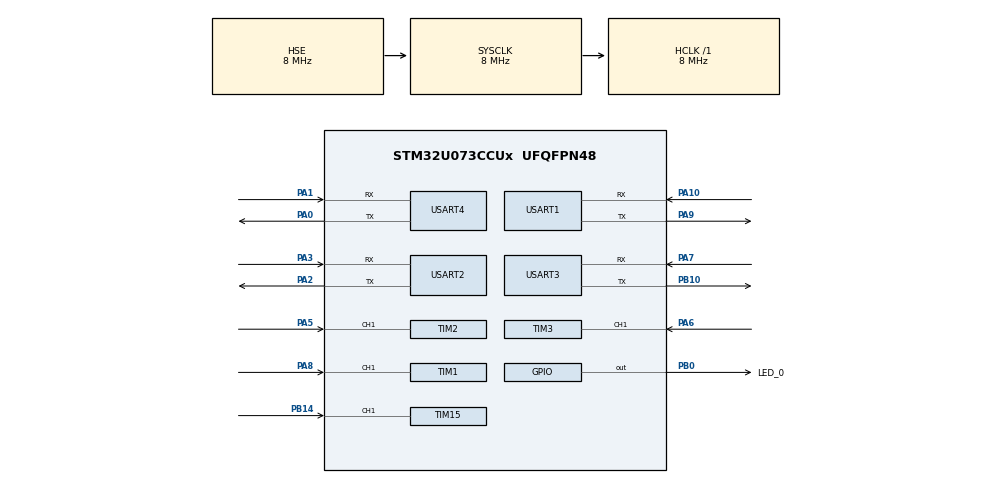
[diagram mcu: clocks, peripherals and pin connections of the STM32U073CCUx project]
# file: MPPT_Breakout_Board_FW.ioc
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Dma.Request0=USART4_RX
Dma.Request1=USART4_TX
Dma.Request2=USART3_RX
Dma.Request3=USART3_TX
Dma.USART3_RX.2.Direction=DMA_PERIPH_TO_MEMORY
Dma.USART3_RX.2.EventEnable=DISABLE
Dma.USART3_RX.2.Instance=DMA1_Channel3
Dma.USART3_RX.2.MemDataAlignment=DMA_MDATAALIGN_BYTE
Dma.USART3_RX.2.MemInc=DMA_MINC_ENABLE
Dma.USART3_RX.2.Mode=DMA_NORMAL
Dma.USART3_RX.2.PeriphDataAlignment=DMA_PDATAALIGN_BYTE
Dma.USART3_RX.2.PeriphInc=DMA_PINC_DISABLE
Dma.USART3_RX.2.Polarity=HAL_DMAMUX_REQ_GEN_RISING
Dma.USART3_RX.2.Priority=DMA_PRIORITY_LOW
Dma.USART3_RX.2.RequestNumber=1
Dma.USART3_RX.2.SignalID=NONE
Dma.USART3_RX.2.SyncEnable=DISABLE
Dma.USART3_RX.2.SyncPolarity=HAL_DMAMUX_SYNC_NO_EVENT
Dma.USART3_RX.2.SyncRequestNumber=1
Dma.USART3_RX.2.SyncSignalID=NONE
Dma.USART3_TX.3.Direction=DMA_MEMORY_TO_PERIPH
Dma.USART3_TX.3.EventEnable=DISABLE
Dma.USART3_TX.3.Instance=DMA1_Channel4
Dma.USART3_TX.3.MemDataAlignment=DMA_MDATAALIGN_BYTE
Dma.USART3_TX.3.MemInc=DMA_MINC_ENABLE
Dma.USART3_TX.3.Mode=DMA_NORMAL
Dma.USART3_TX.3.PeriphDataAlignment=DMA_PDATAALIGN_BYTE
Dma.USART3_TX.3.PeriphInc=DMA_PINC_DISABLE
Dma.USART3_TX.3.Polarity=HAL_DMAMUX_REQ_GEN_RISING
Dma.USART3_TX.3.Priority=DMA_PRIORITY_LOW
Dma.USART3_TX.3.RequestNumber=1
Dma.USART3_TX.3.SignalID=NONE
Dma.USART3_TX.3.SyncEnable=DISABLE
Dma.USART3_TX.3.SyncPolarity=HAL_DMAMUX_SYNC_NO_EVENT
Dma.USART3_TX.3.SyncRequestNumber=1
Dma.USART3_TX.3.SyncSignalID=NONE
Dma.USART4_RX.0.Direction=DMA_PERIPH_TO_MEMORY
Dma.USART4_RX.0.EventEnable=DISABLE
Dma.USART4_RX.0.Instance=DMA1_Channel1
Dma.USART4_RX.0.MemDataAlignment=DMA_MDATAALIGN_BYTE
Dma.USART4_RX.0.MemInc=DMA_MINC_ENABLE
Dma.USART4_RX.0.Mode=DMA_NORMAL
Dma.USART4_RX.0.PeriphDataAlignment=DMA_PDATAALIGN_BYTE
Dma.USART4_RX.0.PeriphInc=DMA_PINC_DISABLE
Dma.USART4_RX.0.Polarity=HAL_DMAMUX_REQ_GEN_RISING
Dma.USART4_RX.0.Priority=DMA_PRIORITY_LOW
Dma.USART4_RX.0.RequestNumber=1
Dma.USART4_RX.0.SignalID=NONE
Dma.USART4_RX.0.SyncEnable=DISABLE
Dma.USART4_RX.0.SyncPolarity=HAL_DMAMUX_SYNC_NO_EVENT
Dma.USART4_RX.0.SyncRequestNumber=1
Dma.USART4_RX.0.SyncSignalID=NONE
Dma.USART4_TX.1.Direction=DMA_MEMORY_TO_PERIPH
Dma.USART4_TX.1.EventEnable=DISABLE
Dma.USART4_TX.1.Instance=DMA1_Channel2
Dma.USART4_TX.1.MemDataAlignment=DMA_MDATAALIGN_BYTE
Dma.USART4_TX.1.MemInc=DMA_MINC_ENABLE
Dma.USART4_TX.1.Mode=DMA_NORMAL
Dma.USART4_TX.1.PeriphDataAlignment=DMA_PDATAALIGN_BYTE
Dma.USART4_TX.1.PeriphInc=DMA_PINC_DISABLE
Dma.USART4_TX.1.Polarity=HAL_DMAMUX_REQ_GEN_RISING
Dma.USART4_TX.1.Priority=DMA_PRIORITY_LOW
Dma.USART4_TX.1.RequestNumber=1
Dma.USART4_TX.1.SignalID=NONE
Dma.USART4_TX.1.SyncEnable=DISABLE
Dma.USART4_TX.1.SyncPolarity=HAL_DMAMUX_SYNC_NO_EVENT
Dma.USART4_TX.1.SyncRequestNumber=1
Dma.USART4_TX.1.SyncSignalID=NONE
Mcu.Family=STM32U0
Mcu.Name=STM32U073CCUx
Mcu.Package=UFQFPN48
NVIC.DMA1_Ch4_7_DMA2_Ch1_5_DMAMUX_OVR_IRQn=true\:0\:0\:false\:false\:true\:false\:true\:true
NVIC.DMA1_Channel1_IRQn=true\:0\:0\:false\:false\:true\:false\:true\:true
NVIC.DMA1_Channel2_3_IRQn=true\:0\:0\:false\:false\:true\:false\:true\:true
NVIC.PriorityGroup=NVIC_PRIORITYGROUP_2
NVIC.USART3_LPUART1_IRQn=true\:0\:0\:false\:false\:true\:true\:true\:true
NVIC.USART4_LPUART3_IRQn=true\:0\:0\:false\:false\:true\:true\:true\:true
PA0.Mode=Asynchronous
PA0.Signal=USART4_TX
PA1.Mode=Asynchronous
PA1.Signal=USART4_RX
PA10.Mode=Asynchronous
PA10.Signal=USART1_RX
PA13\ (SWDIO).Mode=Serial_Wire
PA13\ (SWDIO).Signal=DEBUG_JTMS-SWDIO
PA14\ (SWCLK).Mode=Serial_Wire
PA14\ (SWCLK).Signal=DEBUG_JTCK-SWCLK
PA2.Mode=Asynchronous
PA2.Signal=USART2_TX
PA3.Mode=Asynchronous
PA3.Signal=USART2_RX
PA5.Signal=S_TIM2_CH1_ETR
PA6.Signal=S_TIM3_CH1
PA7.Mode=Asynchronous
PA7.Signal=USART3_RX
PA8.Signal=S_TIM1_CH1
PA9.Mode=Asynchronous
PA9.Signal=USART1_TX
PB0.GPIO_Label=LED_0
PB0.Signal=GPIO_Output
PB10.Mode=Asynchronous
PB10.Signal=USART3_TX
PB14.Signal=S_TIM15_CH1
PF0-OSC_IN.Mode=HSE-External-Oscillator
PF0-OSC_IN.Signal=RCC_OSC_IN
PF1-OSC_OUT.Mode=HSE-External-Oscillator
PF1-OSC_OUT.Signal=RCC_OSC_OUT
ProjectManager.HeapSize=0x200
ProjectManager.StackSize=0x400
ProjectManager.TargetToolchain=CMake
RCC.ADCFreq_Value=8000000
RCC.AHBFreq_Value=8000000
RCC.CortexFreq_Value=8000000
RCC.HCLKFreq_Value=8000000
RCC.HSE_VALUE=8000000
RCC.HSI48_VALUE=48000000
RCC.HSI_VALUE=16000000
RCC.LSE_VALUE=32768
RCC.MSI_VALUE=4000000
RCC.PLLSourceVirtual=RCC_PLLSOURCE_HSE
RCC.SYSCLKFreq_VALUE=8000000
RCC.SYSCLKSource=RCC_SYSCLKSOURCE_HSE
RCC.VCOOutputFreq_Value=32000000
SH.S_TIM15_CH1.0=TIM15_CH1,Input_Capture1_from_TI1
SH.S_TIM1_CH1.0=TIM1_CH1,Input_Capture1_from_TI1
SH.S_TIM2_CH1_ETR.0=TIM2_CH1,Input_Capture1_from_TI1
SH.S_TIM3_CH1.0=TIM3_CH1,Input_Capture1_from_TI1
TIM1.Channel-Input_Capture1_from_TI1=TIM_CHANNEL_1
TIM15.Channel-Input_Capture1_from_TI1=TIM_CHANNEL_1
TIM2.Channel-Input_Capture1_from_TI1=TIM_CHANNEL_1
TIM3.Channel-Input_Capture1_from_TI1=TIM_CHANNEL_1
USART1.VirtualMode-Asynchronous=VM_ASYNC
USART2.VirtualMode-Asynchronous=VM_ASYNC
USART3.VirtualMode-Asynchronous=VM_ASYNC
USART4.VirtualMode-Asynchronous=VM_ASYNC
VP_PWR_VS_SECSignals.Mode=Security/Privilege
VP_TIM1_VS_ClockSourceINT.Mode=Internal
VP_TIM2_VS_ClockSourceINT.Mode=Internal
board=custom

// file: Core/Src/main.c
/* USER CODE BEGIN Header */
/**
  ******************************************************************************
  * @file           : main.c
  * @brief          : Main program body
  ******************************************************************************
  * @attention
  *
  * Copyright (c) 2024 STMicroelectronics.
  * All rights reserved.
  *
  * This software is licensed under terms that can be found in the LICENSE file
  * in the root directory of this software component.
  * If no LICENSE file comes with this software, it is provided AS-IS.
  *
  ******************************************************************************
  */
/* USER CODE END Header */
#include "main.h"
#include "dma.h"
#include "tim.h"
#include "usart.h"
#include "gpio.h"

/* USER CODE BEGIN Includes */
#include "superloop.h" // Only User Added Include
/* USER CODE END Includes */

void SystemClock_Config(void);

int main(void)
{

  /* MCU Configuration--------------------------------------------------------*/

  /* Reset of all peripherals, Initializes the Flash interface and the Systick. */
  HAL_Init();

  /* Configure the system clock */
  SystemClock_Config();

  /* Initialize all configured peripherals */
  MX_GPIO_Init();
  MX_DMA_Init();
  MX_TIM1_Init();
  MX_TIM2_Init();
  MX_TIM3_Init();
  MX_TIM15_Init();
  MX_USART1_UART_Init();
  MX_USART2_UART_Init();
  MX_USART3_UART_Init();
  MX_USART4_UART_Init();
  /* USER CODE BEGIN 2 */

  /* Enter Superloop Initialize - One of two User Added functions in main.c */
  superloop_init();

  /* USER CODE END 2 */

  /* Infinite loop */
  /* USER CODE BEGIN WHILE */
  while (1)
  {
    /* Enter Superloop - One of two User Added functions in main.c */
    superloop_run();

    /* USER CODE END WHILE */

  }
}

void SystemClock_Config(void)
{
  RCC_OscInitTypeDef RCC_OscInitStruct = {0};
  RCC_ClkInitTypeDef RCC_ClkInitStruct = {0};

  /** Configure the main internal regulator output voltage
  */
  HAL_PWREx_ControlVoltageScaling(PWR_REGULATOR_VOLTAGE_SCALE2);

  /** Initializes the RCC Oscillators according to the specified parameters
  * in the RCC_OscInitTypeDef structure.
  */
  RCC_OscInitStruct.OscillatorType = RCC_OSCILLATORTYPE_HSE;
  RCC_OscInitStruct.HSEState = RCC_HSE_ON;
  RCC_OscInitStruct.PLL.PLLState = RCC_PLL_NONE;
  if (HAL_RCC_OscConfig(&RCC_OscInitStruct) != HAL_OK)
  {
    Error_Handler();
  }

  /** Initializes the CPU, AHB and APB buses clocks
  */
  RCC_ClkInitStruct.ClockType = RCC_CLOCKTYPE_HCLK|RCC_CLOCKTYPE_SYSCLK
                              |RCC_CLOCKTYPE_PCLK1;
  RCC_ClkInitStruct.SYSCLKSource = RCC_SYSCLKSOURCE_HSE;
  RCC_ClkInitStruct.AHBCLKDivider = RCC_SYSCLK_DIV1;
  RCC_ClkInitStruct.APB1CLKDivider = RCC_HCLK_DIV1;

  if (HAL_RCC_ClockConfig(&RCC_ClkInitStruct, FLASH_LATENCY_0) != HAL_OK)
  {
    Error_Handler();
  }
}

void Error_Handler(void)
{
  /* USER CODE BEGIN Error_Handler_Debug */
  /* User can add his own implementation to report the HAL error return state */
  __disable_irq();
  while (1)
  {
    /* Blink LED Quickly */
    HAL_GPIO_TogglePin(LED_0_GPIO_Port, LED_0_Pin);
    HAL_Delay(100);
  }
  /* USER CODE END Error_Handler_Debug */
}
